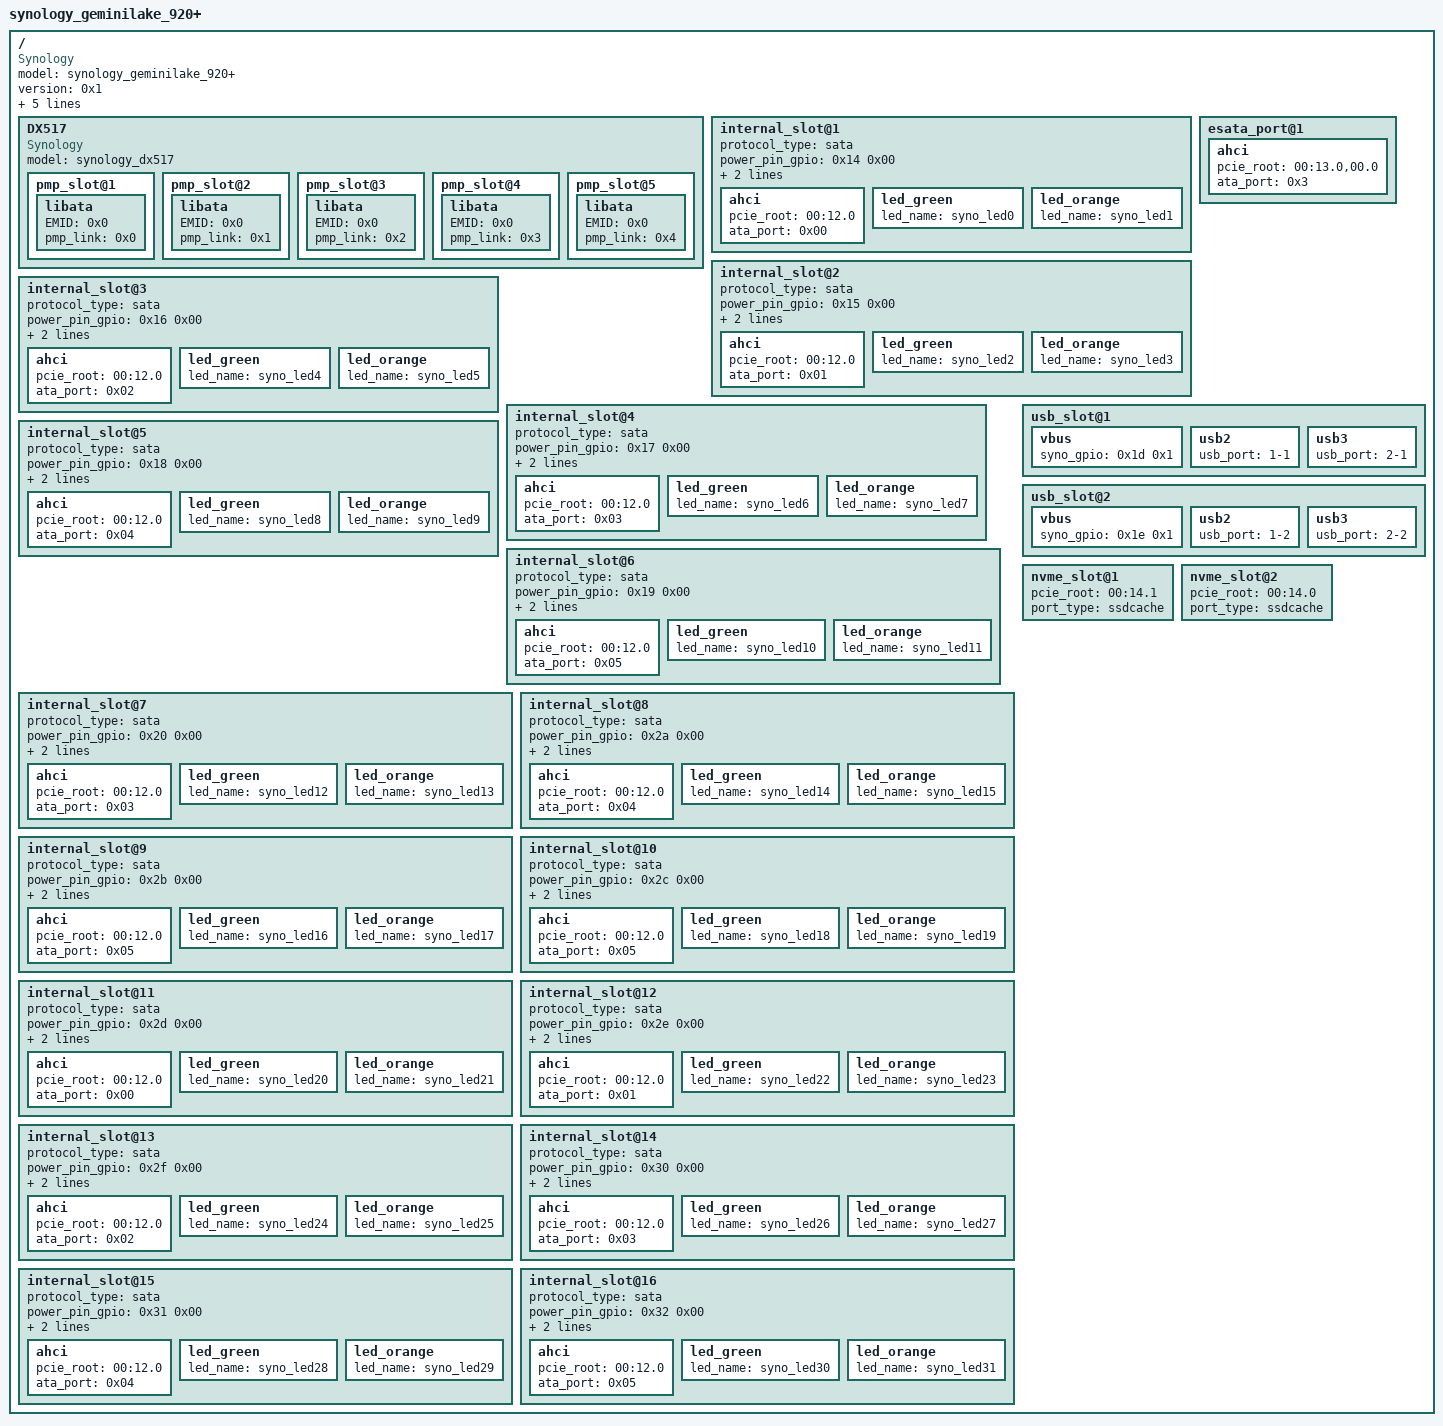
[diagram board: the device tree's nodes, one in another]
/dts-v1/;

/ {
	compatible = "Synology";
	model = "synology_geminilake_920+";
	version = <0x1>;
	syno_spinup_group = <0x2 0x1 0x1>;
	syno_spinup_group_delay = <0xb>;
	syno_hdd_powerup_seq = "true";
	syno_cmos_reg_secure_flash = <0x66>;
	syno_cmos_reg_secure_boot = <0x68>;

	DX517 {
		compatible = "Synology";
		model = "synology_dx517";

		pmp_slot@1 {

			libata {
				EMID = <0x0>;
				pmp_link = <0x0>;
			};
		};

		pmp_slot@2 {

			libata {
				EMID = <0x0>;
				pmp_link = <0x1>;
			};
		};

		pmp_slot@3 {

			libata {
				EMID = <0x0>;
				pmp_link = <0x2>;
			};
		};

		pmp_slot@4 {

			libata {
				EMID = <0x0>;
				pmp_link = <0x3>;
			};
		};

		pmp_slot@5 {

			libata {
				EMID = <0x0>;
				pmp_link = <0x4>;
			};
		};
	};

	internal_slot@1 {
		protocol_type = "sata";
		power_pin_gpio = <0x14 0x00>;
		detect_pin_gpio = <0x23 0x01>;
		led_type = "lp3943";

		ahci { pcie_root = "00:12.0";
			ata_port = <0x00>;
		};

		led_green {
			led_name = "syno_led0";
		};

		led_orange {
			led_name = "syno_led1";
		};
	};

	internal_slot@2 {
		protocol_type = "sata";
		power_pin_gpio = <0x15 0x00>;
		detect_pin_gpio = <0x24 0x01>;
		led_type = "lp3943";

		ahci { pcie_root = "00:12.0";
			ata_port = <0x01>;
		};

		led_green {
			led_name = "syno_led2";
		};

		led_orange {
			led_name = "syno_led3";
		};
	};

	internal_slot@3 {
		protocol_type = "sata";
		power_pin_gpio = <0x16 0x00>;
		detect_pin_gpio = <0x25 0x01>;
		led_type = "lp3943";

		ahci { pcie_root = "00:12.0";
			ata_port = <0x02>;
		};

		led_green {
			led_name = "syno_led4";
		};

		led_orange {
			led_name = "syno_led5";
		};
	};

	internal_slot@4 {
		protocol_type = "sata";
		power_pin_gpio = <0x17 0x00>;
		detect_pin_gpio = <0x26 0x01>;
		led_type = "lp3943";

		ahci { pcie_root = "00:12.0";
			ata_port = <0x03>;
		};

		led_green {
			led_name = "syno_led6";
		};

		led_orange {
			led_name = "syno_led7";
		};
	};


	internal_slot@5 {
		protocol_type = "sata";
		power_pin_gpio = <0x18 0x00>;
		detect_pin_gpio = <0x27 0x01>;
		led_type = "lp3943";

		ahci { pcie_root = "00:12.0";
			ata_port = <0x04>;
		};

		led_green {
			led_name = "syno_led8";
		};

		led_orange {
			led_name = "syno_led9";
		};
	};


	internal_slot@6 {
		protocol_type = "sata";
		power_pin_gpio = <0x19 0x00>;
		detect_pin_gpio = <0x28 0x01>;
		led_type = "lp3943";

		ahci { pcie_root = "00:12.0";
			ata_port = <0x05>;
		};

		led_green {
			led_name = "syno_led10";
		};

		led_orange {
			led_name = "syno_led11";
		};
	};

	internal_slot@7 {
		protocol_type = "sata";
		power_pin_gpio = <0x20 0x00>;
		detect_pin_gpio = <0x29 0x01>;
		led_type = "lp3943";

		ahci { pcie_root = "00:12.0";
			ata_port = <0x03>;
		};

		led_green {
			led_name = "syno_led12";
		};

		led_orange {
			led_name = "syno_led13";
		};
	};


	internal_slot@8 {
		protocol_type = "sata";
		power_pin_gpio = <0x2a 0x00>;
		detect_pin_gpio = <0x30 0x01>;
		led_type = "lp3943";

		ahci { pcie_root = "00:12.0";
			ata_port = <0x04>;
		};

		led_green {
			led_name = "syno_led14";
		};

		led_orange {
			led_name = "syno_led15";
		};
	};


	internal_slot@9 {
		protocol_type = "sata";
		power_pin_gpio = <0x2b 0x00>;
		detect_pin_gpio = <0x3a 0x01>;
		led_type = "lp3943";

		ahci { pcie_root = "00:12.0";
			ata_port = <0x05>;
		};

		led_green {
			led_name = "syno_led16";
		};

		led_orange {
			led_name = "syno_led17";
		};
	};

	internal_slot@10 {
		protocol_type = "sata";
		power_pin_gpio = <0x2c 0x00>;
		detect_pin_gpio = <0x3b 0x01>;
		led_type = "lp3943";

		ahci { pcie_root = "00:12.0";
			ata_port = <0x05>;
		};

		led_green {
			led_name = "syno_led18";
		};

		led_orange {
			led_name = "syno_led19";
		};
	};


	internal_slot@11 {
		protocol_type = "sata";
		power_pin_gpio = <0x2d 0x00>;
		detect_pin_gpio = <0x3c 0x01>;
		led_type = "lp3943";

		ahci { pcie_root = "00:12.0";
			ata_port = <0x00>;
		};

		led_green {
			led_name = "syno_led20";
		};

		led_orange {
			led_name = "syno_led21";
		};
	};

	internal_slot@12 {
		protocol_type = "sata";
		power_pin_gpio = <0x2e 0x00>;
		detect_pin_gpio = <0x3d 0x01>;
		led_type = "lp3943";

		ahci { pcie_root = "00:12.0";
			ata_port = <0x01>;
		};

		led_green {
			led_name = "syno_led22";
		};

		led_orange {
			led_name = "syno_led23";
		};
	};

	internal_slot@13 {
		protocol_type = "sata";
		power_pin_gpio = <0x2f 0x00>;
		detect_pin_gpio = <0x3e 0x01>;
		led_type = "lp3943";

		ahci { pcie_root = "00:12.0";
			ata_port = <0x02>;
		};

		led_green {
			led_name = "syno_led24";
		};

		led_orange {
			led_name = "syno_led25";
		};
	};

	internal_slot@14 {
		protocol_type = "sata";
		power_pin_gpio = <0x30 0x00>;
		detect_pin_gpio = <0x3f 0x01>;
		led_type = "lp3943";

		ahci { pcie_root = "00:12.0";
			ata_port = <0x03>;
		};

		led_green {
			led_name = "syno_led26";
		};

		led_orange {
			led_name = "syno_led27";
		};
	};


	internal_slot@15 {
		protocol_type = "sata";
		power_pin_gpio = <0x31 0x00>;
		detect_pin_gpio = <0x40 0x01>;
		led_type = "lp3943";

		ahci { pcie_root = "00:12.0";
			ata_port = <0x04>;
		};

		led_green {
			led_name = "syno_led28";
		};

		led_orange {
			led_name = "syno_led29";
		};
	};


	internal_slot@16 {
		protocol_type = "sata";
		power_pin_gpio = <0x32 0x00>;
		detect_pin_gpio = <0x41 0x01>;
		led_type = "lp3943";

		ahci { pcie_root = "00:12.0";
			ata_port = <0x05>;
		};

		led_green {
			led_name = "syno_led30";
		};

		led_orange {
			led_name = "syno_led31";
		};
	};

	esata_port@1 {

		ahci {
			pcie_root = "00:13.0,00.0";
			ata_port = <0x3>;
		};
	};

	usb_slot@1 {

		vbus {
			syno_gpio = <0x1d 0x1>;
		};

		usb2 {
			usb_port = "1-1";
		};

		usb3 {
			usb_port = "2-1";
		};
	};

	usb_slot@2 {

		vbus {
			syno_gpio = <0x1e 0x1>;
		};

		usb2 {
			usb_port = "1-2";
		};

		usb3 {
			usb_port = "2-2";
		};
	};

	nvme_slot@1 {
		pcie_root = "00:14.1";
		port_type = "ssdcache";
	};

	nvme_slot@2 {
		pcie_root = "00:14.0";
		port_type = "ssdcache";
	};
};
